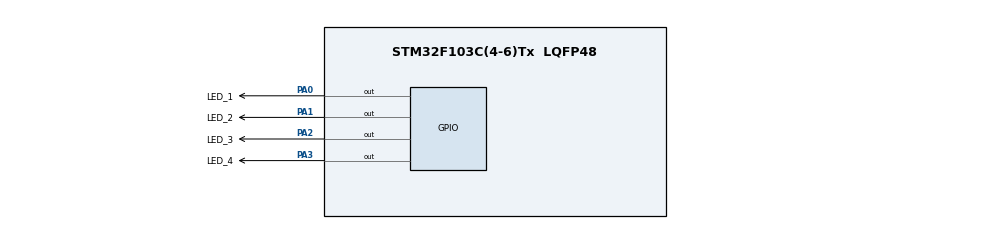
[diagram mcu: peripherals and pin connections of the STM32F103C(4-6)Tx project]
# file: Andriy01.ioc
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Mcu.Family=STM32F1
Mcu.Name=STM32F103C(4-6)Tx
Mcu.Package=LQFP48
NVIC.PriorityGroup=NVIC_PRIORITYGROUP_4
PA0-WKUP.GPIO_Label=LED_1
PA0-WKUP.Signal=GPIO_Output
PA1.GPIO_Label=LED_2
PA1.Signal=GPIO_Output
PA2.GPIO_Label=LED_3
PA2.Signal=GPIO_Output
PA3.GPIO_Label=LED_4
PA3.Signal=GPIO_Output
ProjectManager.HeapSize=0x200
ProjectManager.StackSize=0x400
ProjectManager.TargetToolchain=STM32CubeIDE
RCC.APB1Freq_Value=8000000
RCC.APB2Freq_Value=8000000
VP_SYS_VS_ND.Mode=No_Debug
board=custom

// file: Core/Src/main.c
/* USER CODE BEGIN Header */
/**
  ******************************************************************************
  * @file           : main.c
  * @brief          : Main program body
  ******************************************************************************
  * @attention
  *
  * Copyright (c) 2022 STMicroelectronics.
  * All rights reserved.
  *
  * This software is licensed under terms that can be found in the LICENSE file
  * in the root directory of this software component.
  * If no LICENSE file comes with this software, it is provided AS-IS.
  *
  ******************************************************************************
  */
/* USER CODE END Header */
#include "main.h"
#include "gpio.h"

void SystemClock_Config(void);

int main(void)
{

  /* MCU Configuration--------------------------------------------------------*/

  /* Reset of all peripherals, Initializes the Flash interface and the Systick. */
  HAL_Init();

  /* Configure the system clock */
  SystemClock_Config();

  /* Initialize all configured peripherals */
  MX_GPIO_Init();

  /* Infinite loop */
  /* USER CODE BEGIN WHILE */
  while (1)
  {
	  HAL_GPIO_TogglePin(LED_1_GPIO_Port, LED_1_Pin);
	        HAL_Delay(600);
	        HAL_GPIO_TogglePin(LED_2_GPIO_Port, LED_2_Pin);
	        HAL_Delay(600);
	        HAL_GPIO_TogglePin(LED_3_GPIO_Port, LED_3_Pin);
	        HAL_Delay(600);
	        HAL_GPIO_TogglePin(LED_4_GPIO_Port, LED_4_Pin);
	        HAL_Delay(600);
	  /* USER CODE END WHILE */

  }
}

void SystemClock_Config(void)
{
  RCC_OscInitTypeDef RCC_OscInitStruct = {0};
  RCC_ClkInitTypeDef RCC_ClkInitStruct = {0};

  /** Initializes the RCC Oscillators according to the specified parameters
  * in the RCC_OscInitTypeDef structure.
  */
  RCC_OscInitStruct.OscillatorType = RCC_OSCILLATORTYPE_HSI;
  RCC_OscInitStruct.HSIState = RCC_HSI_ON;
  RCC_OscInitStruct.HSICalibrationValue = RCC_HSICALIBRATION_DEFAULT;
  RCC_OscInitStruct.PLL.PLLState = RCC_PLL_NONE;
  if (HAL_RCC_OscConfig(&RCC_OscInitStruct) != HAL_OK)
  {
    Error_Handler();
  }
  /** Initializes the CPU, AHB and APB buses clocks
  */
  RCC_ClkInitStruct.ClockType = RCC_CLOCKTYPE_HCLK|RCC_CLOCKTYPE_SYSCLK
                              |RCC_CLOCKTYPE_PCLK1|RCC_CLOCKTYPE_PCLK2;
  RCC_ClkInitStruct.SYSCLKSource = RCC_SYSCLKSOURCE_HSI;
  RCC_ClkInitStruct.AHBCLKDivider = RCC_SYSCLK_DIV1;
  RCC_ClkInitStruct.APB1CLKDivider = RCC_HCLK_DIV1;
  RCC_ClkInitStruct.APB2CLKDivider = RCC_HCLK_DIV1;

  if (HAL_RCC_ClockConfig(&RCC_ClkInitStruct, FLASH_LATENCY_0) != HAL_OK)
  {
    Error_Handler();
  }
}

void Error_Handler(void)
{
  __disable_irq();
  while (1)
  {
  }
}
